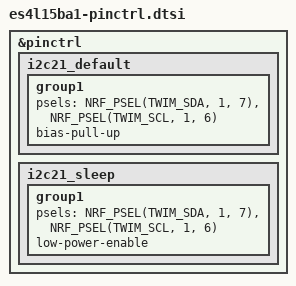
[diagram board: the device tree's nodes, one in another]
&pinctrl {
	i2c21_default: i2c21_default {
		group1 {
			psels = <NRF_PSEL(TWIM_SDA, 1, 7)>,
					<NRF_PSEL(TWIM_SCL, 1, 6)>;
			bias-pull-up;
		};
	};

	i2c21_sleep: i2c21_sleep {
		group1 {
			psels = <NRF_PSEL(TWIM_SDA, 1, 7)>,
					<NRF_PSEL(TWIM_SCL, 1, 6)>;
			low-power-enable;
		};
	};
};
